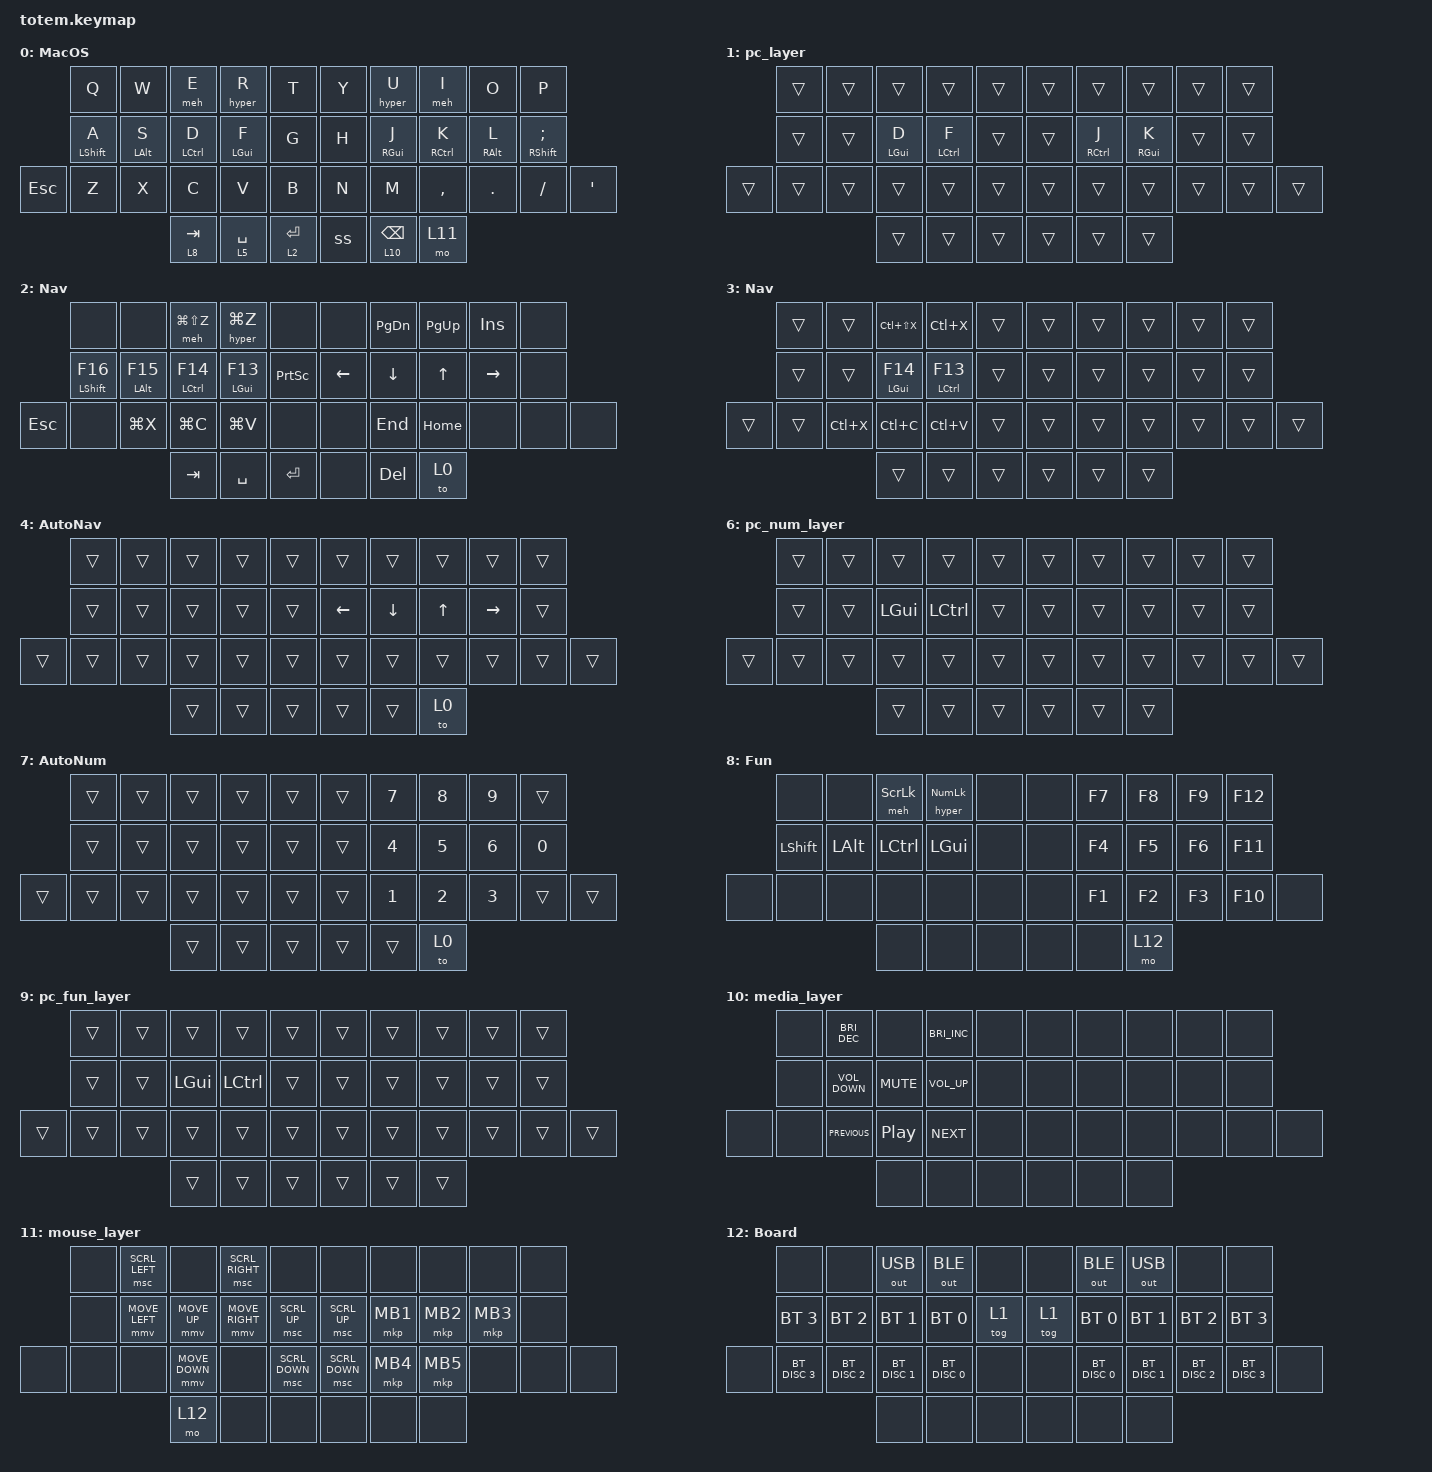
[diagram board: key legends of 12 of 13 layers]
#include <behaviors/num_word.dtsi>
#include <behaviors.dtsi>
#include <dt-bindings/zmk/bt.h>
#include <dt-bindings/zmk/keys.h>
#include <dt-bindings/zmk/outputs.h>
#include <dt-bindings/zmk/pointing.h>

#define LEFT_HAND_POS 0 1 2 3 4 10 11 12 13 14 20 21 22 23 24 25
#define RIGHT_HAND_POS 5 6 7 8 9 15 16 17 18 19 26 27 28 29 30 31
#define THUMB_POS 32 33 34 35 36 37

/ {
    macros {
        meh: meh {
            compatible = "zmk,behavior-macro";
            #binding-cells = <0>;
            wait-ms = <0>;
            tap-ms = <0>;
            bindings =
                <&macro_press>,
                <&kp LCTRL &kp LSHFT &kp LALT>,
                <&macro_pause_for_release>,
                <&macro_release>,
                <&kp LCTRL &kp LSHFT &kp LALT>;
        };

        hyper: hyper {
            compatible = "zmk,behavior-macro";
            #binding-cells = <0>;
            wait-ms = <0>;
            tap-ms = <0>;
            bindings =
                <&macro_press>,
                <&kp LCTRL &kp LSHFT &kp LALT &kp LGUI>,
                <&macro_pause_for_release>,
                <&macro_release>,
                <&kp LCTRL &kp LSHFT &kp LALT &kp LGUI>;
        };
    };

    behaviors {
        hml: home_row_mod_left {
            compatible = "zmk,behavior-hold-tap";
            #binding-cells = <2>;
            flavor = "balanced";
            tapping-term-ms = <280>;
            quick-tap-ms = <300>;
            require-prior-idle-ms = <150>;
            retro-tap;
            bindings = <&kp>, <&kp>;

            hold-trigger-key-positions = <RIGHT_HAND_POS THUMB_POS>;
            hold-trigger-on-release;
        };

        hmr: home_row_mod_right {
            compatible = "zmk,behavior-hold-tap";
            #binding-cells = <2>;
            flavor = "balanced";
            tapping-term-ms = <280>;
            quick-tap-ms = <300>;
            require-prior-idle-ms = <150>;
            retro-tap;
            bindings = <&kp>, <&kp>;

            hold-trigger-key-positions = <LEFT_HAND_POS THUMB_POS>;
            hold-trigger-on-release;
        };

        lmeh: left_meh_mod {
            compatible = "zmk,behavior-hold-tap";
            #binding-cells = <2>;
            flavor = "balanced";
            tapping-term-ms = <280>;
            quick-tap-ms = <300>;
            require-prior-idle-ms = <150>;
            retro-tap;
            bindings = <&meh>, <&kp>;

            hold-trigger-key-positions = <RIGHT_HAND_POS THUMB_POS>;
            hold-trigger-on-release;
        };

        lhyp: left_hyper_mod {
            compatible = "zmk,behavior-hold-tap";
            #binding-cells = <2>;
            flavor = "balanced";
            tapping-term-ms = <280>;
            quick-tap-ms = <300>;
            require-prior-idle-ms = <150>;
            retro-tap;
            bindings = <&hyper>, <&kp>;

            hold-trigger-key-positions = <RIGHT_HAND_POS THUMB_POS>;
            hold-trigger-on-release;
        };

        rhyp: right_hyper_mod {
            compatible = "zmk,behavior-hold-tap";
            #binding-cells = <2>;
            flavor = "balanced";
            tapping-term-ms = <280>;
            quick-tap-ms = <300>;
            require-prior-idle-ms = <150>;
            retro-tap;
            bindings = <&hyper>, <&kp>;

            hold-trigger-key-positions = <LEFT_HAND_POS THUMB_POS>;
            hold-trigger-on-release;
        };

        rmeh: right_meh_mod {
            compatible = "zmk,behavior-hold-tap";
            #binding-cells = <2>;
            flavor = "balanced";
            tapping-term-ms = <280>;
            quick-tap-ms = <300>;
            require-prior-idle-ms = <150>;
            retro-tap;
            bindings = <&meh>, <&kp>;

            hold-trigger-key-positions = <LEFT_HAND_POS THUMB_POS>;
            hold-trigger-on-release;
        };

        lts: layer_tap_sticky {
            compatible = "zmk,behavior-hold-tap";
            bindings = <&mo>, <&sk>;

            #binding-cells = <2>;
            tapping-term-ms = <200>;
        };

        ss: super_shift {
            compatible = "zmk,behavior-tap-dance";
            #binding-cells = <0>;
            bindings = <&lts 2 LEFT_SHIFT>, <&caps_word>;
        };

        htc: hold_tap_combo {
            compatible = "zmk,behavior-hold-tap";
            bindings = <&kp>, <&kp>;

            #binding-cells = <2>;
            tapping-term-ms = <185>;
            require-prior-idle-ms = <20>;
            flavor = "tap-preferred";
        };

        nav_word: nav_word {
            compatible = "zmk,behavior-auto-layer";
            #binding-cells = <1>;
            continue-list = <LEFT DOWN UP RIGHT PG_DN PG_UP INSERT END HOME TAB BACKSPACE DELETE K_UNDO K_REDO>;
            ignore-modifiers;
        };

        mht: mod_hold_transparent {
            compatible = "zmk,behavior-hold-tap";
            bindings = <&kp>, <&trans>;

            #binding-cells = <2>;
            tapping-term-ms = <200>;
            require-prior-idle-ms = <200>;
            flavor = "tap-unless-interrupted";
        };

        hypht: hyper_hold_transparent {
            compatible = "zmk,behavior-hold-tap";
            bindings = <&lhyp>, <&trans>;

            #binding-cells = <2>;
            tapping-term-ms = <200>;
            require-prior-idle-ms = <200>;
            flavor = "tap-unless-interrupted";
        };

        mehht: meh_hold_transparent {
            compatible = "zmk,behavior-hold-tap";
            bindings = <&lmeh>, <&trans>;

            #binding-cells = <2>;
            tapping-term-ms = <200>;
            require-prior-idle-ms = <200>;
            flavor = "tap-unless-interrupted";
        };
    };

    /* Ported from fleetsing/zmk-config-old; old 3x5+3 bottom-row positions are shifted for Totem. */

    combos {
        compatible = "zmk,combos";

        /* Symbol combos: slightly more time to chord intentionally, modest idle gate. */

        combo_euro_dollar {
            bindings = <&htc LA(NUMBER_4) RS(NUMBER_4)>;
            key-positions = <4 14>;
            timeout-ms = <32>;
            require-prior-idle-ms = <60>;
            layers = <0 5>;
        };

        combo_pc_euro_dollar {
            bindings = <&htc RA(NUMBER_4) RA(E)>;
            key-positions = <4 14>;
            timeout-ms = <32>;
            require-prior-idle-ms = <60>;
            layers = <1 6>;
        };

        combo_at_caret {
            bindings = <&htc RS(RIGHT_BRACKET) LA(NUMBER_2)>;
            key-positions = <14 25>;
            timeout-ms = <32>;
            require-prior-idle-ms = <60>;
            layers = <0 5 1 6>;
        };

        combo_colon_semicolon {
            bindings = <&htc RS(COMMA) RS(PERIOD)>;
            key-positions = <3 13>;
            timeout-ms = <32>;
            require-prior-idle-ms = <60>;
            layers = <0 5 1 6>;
        };

        combo_apostrophe_quote {
            bindings = <&htc RS(NUMBER_2) BACKSLASH>;
            key-positions = <13 24>;
            timeout-ms = <32>;
            require-prior-idle-ms = <60>;
            layers = <0 5 1 6>;
        };

        combo_plus_equals {
            bindings = <&htc RS(NUMBER_0) MINUS>;
            key-positions = <12 2>;
            timeout-ms = <32>;
            require-prior-idle-ms = <60>;
            layers = <0 5 1 6>;
        };

        combo_minus_underscore {
            bindings = <&htc RS(SLASH) SLASH>;
            key-positions = <12 23>;
            timeout-ms = <32>;
            require-prior-idle-ms = <60>;
            layers = <0 5 1 6>;
        };

        combo_asterisk_percentage {
            bindings = <&htc RS(NUMBER_5) RS(BACKSLASH)>;
            key-positions = <1 11>;
            timeout-ms = <32>;
            require-prior-idle-ms = <60>;
            layers = <0 5 1 6>;
        };

        combo_slash_backslash {
            bindings = <&htc RS(LA(NUMBER_7)) RS(NUMBER_7)>;
            key-positions = <11 22>;
            timeout-ms = <32>;
            require-prior-idle-ms = <60>;
            layers = <0 5>;
        };

        combo_pc_slash_backslash {
            bindings = <&htc RA(EQUAL) RS(NUMBER_7)>;
            key-positions = <11 22>;
            timeout-ms = <32>;
            require-prior-idle-ms = <60>;
            layers = <1 6>;
        };

        combo_ampersand_hash {
            bindings = <&htc RS(NUMBER_3) RS(NUMBER_6)>;
            key-positions = <5 15>;
            timeout-ms = <32>;
            require-prior-idle-ms = <60>;
            layers = <0 5 1 6>;
        };

        combo_tilde_pipe {
            bindings = <&htc LA(NUMBER_7) LA(RIGHT_BRACKET)>;
            key-positions = <15 26>;
            timeout-ms = <32>;
            require-prior-idle-ms = <60>;
            layers = <0 5>;
        };

        combo_pc_tilde_pipe {
            bindings = <&htc RA(BACKSLASH) RA(RIGHT_BRACKET)>;
            key-positions = <15 26>;
            timeout-ms = <32>;
            require-prior-idle-ms = <60>;
            layers = <1 6>;
        };

        combo_left_parenth_brace {
            bindings = <&htc RS(LA(NUMBER_8)) RS(NUMBER_8)>;
            key-positions = <6 16>;
            timeout-ms = <32>;
            require-prior-idle-ms = <60>;
            layers = <0 5>;
        };

        combo_pc_left_parenth_brace {
            bindings = <&htc RA(NUMBER_7) RS(NUMBER_8)>;
            key-positions = <16 6>;
            timeout-ms = <32>;
            require-prior-idle-ms = <60>;
            layers = <1 6>;
        };

        combo_left_bracket_lesser {
            bindings = <&htc GRAVE LA(NUMBER_8)>;
            key-positions = <16 27>;
            timeout-ms = <32>;
            require-prior-idle-ms = <60>;
            layers = <0 5 1 6>;
        };

        combo_right_parenth_brace {
            bindings = <&htc LA(RS(NUMBER_9)) RS(NUMBER_9)>;
            key-positions = <7 17>;
            timeout-ms = <32>;
            require-prior-idle-ms = <60>;
            layers = <0 5>;
        };

        combo_pc_right_parenth_brace {
            bindings = <&htc RA(NUMBER_0) RS(NUMBER_9)>;
            key-positions = <7 17>;
            timeout-ms = <32>;
            require-prior-idle-ms = <60>;
            layers = <1 6>;
        };

        combo_right_bracket_greater {
            bindings = <&htc RS(GRAVE) LA(NUMBER_9)>;
            key-positions = <17 28>;
            timeout-ms = <32>;
            require-prior-idle-ms = <60>;
            layers = <0 5 1 6>;
        };

        combo_grave_infinity {
            bindings = <&htc LA(NUMBER_5) EQUAL>;
            key-positions = <8 18>;
            timeout-ms = <32>;
            require-prior-idle-ms = <60>;
            layers = <0 5 1 6>;
        };

        /* Utility combos: tighter timing, stronger idle gate. */

        combo_tab {
            bindings = <&kp TAB>;
            key-positions = <13 12>;
            timeout-ms = <22>;
            require-prior-idle-ms = <110>;
            layers = <0 1 2 3 5 6>;
        };

        combo_tab_back {
            bindings = <&kp RS(TAB)>;
            key-positions = <12 11>;
            timeout-ms = <22>;
            require-prior-idle-ms = <110>;
            layers = <0 1 2 3 5 6>;
        };

        combo_backspace {
            bindings = <&kp BACKSPACE>;
            key-positions = <16 17>;
            timeout-ms = <22>;
            require-prior-idle-ms = <110>;
            layers = <0 1 2 3 5 6>;
        };

        combo_delete {
            bindings = <&kp DELETE>;
            key-positions = <17 18>;
            timeout-ms = <22>;
            require-prior-idle-ms = <110>;
            layers = <0 1 2 3 5 6>;
        };

        combo_lesseror_trademark {
            bindings = <&mt LA(BACKSLASH) LA(GRAVE)>;
            key-positions = <18 29>;
            timeout-ms = <32>;
            require-prior-idle-ms = <60>;
            layers = <0 5>;
        };

        combo_greateror_copyright {
            bindings = <&mt LA(NUMBER_1) LA(RS(GRAVE))>;
            key-positions = <19 30>;
            timeout-ms = <32>;
            require-prior-idle-ms = <60>;
            layers = <0 5>;
        };

        /* Layer combos: make accidental toggles harder than symbol entry. */

        combo_nav_layer {
            bindings = <&nav_word 4>;
            key-positions = <16 18>;
            timeout-ms = <28>;
            require-prior-idle-ms = <140>;
            layers = <0 1>;
        };

        combo_num_layer {
            bindings = <&num_word 7>;
            key-positions = <27 29>;
            timeout-ms = <28>;
            require-prior-idle-ms = <140>;
            layers = <0 1 2 3>;
        };
    };

    keymap {
        compatible = "zmk,keymap";

        macos_layer {
            bindings = <
            &kp Q              &kp W        &lmeh 0 E     &lhyp 0 R    &kp T          &kp Y  &rhyp 0 U         &rmeh 0 I     &kp O        &kp P
            &hml LEFT_SHIFT A  &hml LALT S  &hml LCTRL D  &hml LGUI F  &kp G          &kp H  &hmr RGUI J       &hmr RCTRL K  &hmr RALT L  &hmr RIGHT_SHIFT SEMI
&kp ESCAPE  &kp Z              &kp X        &kp C         &kp V        &kp B          &kp N  &kp M             &kp COMMA     &kp DOT      &kp SLASH              &kp APOS
                                            &lt 8 TAB     &lt 5 SPACE  &lt 2 ENTER    &ss    &lt 10 BACKSPACE  &mo 11
            >;

            label = "MacOS";
        };

        pc_layer {
            bindings = <
        &trans  &trans  &trans           &trans               &trans    &trans  &trans                &trans            &trans  &trans
        &trans  &trans  &hml LEFT_GUI D  &hml LEFT_CONTROL F  &trans    &trans  &hmr RIGHT_CONTROL J  &hmr RIGHT_GUI K  &trans  &trans
&trans  &trans  &trans  &trans           &trans               &trans    &trans  &trans                &trans            &trans  &trans  &trans
                        &trans           &trans               &trans    &trans  &trans                &trans
            >;
        };

        nav_layer {
            bindings = <
            &none                &none              &lmeh 0 LG(LS(Z))      &lhyp 0 LG(Z)      &none              &none     &kp PG_DN   &kp PG_UP  &kp INSERT  &none
            &hml LEFT_SHIFT F16  &hml LEFT_ALT F15  &hml LEFT_CONTROL F14  &hml LEFT_GUI F13  &kp PRINTSCREEN    &kp LEFT  &kp DOWN    &kp UP     &kp RIGHT   &none
&kp ESCAPE  &none                &kp LG(X)          &kp LG(C)              &kp LG(V)          &none              &none     &kp END     &kp HOME   &none       &none  &none
                                                    &kp TAB                &kp SPACE          &kp ENTER          &none     &kp DELETE  &to 0
            >;

            label = "Nav";
        };

        pc_nav_layer {
            bindings = <
        &trans  &trans     &kp LC(LS(X))      &kp LC(X)              &trans    &trans  &trans  &trans  &trans  &trans
        &trans  &trans     &hml LEFT_GUI F14  &hml LEFT_CONTROL F13  &trans    &trans  &trans  &trans  &trans  &trans
&trans  &trans  &kp LC(X)  &kp LC(C)          &kp LC(V)              &trans    &trans  &trans  &trans  &trans  &trans  &trans
                           &trans             &trans                 &trans    &trans  &trans  &trans
            >;

            label = "Nav ";
        };

        autonav_layer {
            bindings = <
        &trans  &trans  &trans  &trans  &trans    &trans          &trans          &trans        &trans           &trans
        &trans  &trans  &trans  &trans  &trans    &kp LEFT_ARROW  &kp DOWN_ARROW  &kp UP_ARROW  &kp RIGHT_ARROW  &trans
&trans  &trans  &trans  &trans  &trans  &trans    &trans          &trans          &trans        &trans           &trans  &trans
                        &trans  &trans  &trans    &trans          &trans          &to 0
            >;

            label = "AutoNav";
        };

        num_layer {
            bindings = <
       &none           &none         &kp LA(LC(LEFT_SHIFT))  &kp LA(LC(LG(LEFT_SHIFT)))  &none    &none   &kp N7         &kp N8  &kp N9  &none
       &kp LEFT_SHIFT  &kp LEFT_ALT  &kp LEFT_CONTROL        &kp LEFT_GUI                &none    &none   &kp N4         &kp N5  &kp N6  &kp N0
&none  &none           &none         &none                   &none                       &none    &none   &kp N1         &kp N2  &kp N3  &none   &none
                                     &none                   &none                       &none    &kp N0  &kp BACKSPACE  &to 0
            >;

            label = "Num";
        };

        pc_num_layer {
            bindings = <
        &trans  &trans  &trans        &trans            &trans    &trans  &trans  &trans  &trans  &trans
        &trans  &trans  &kp LEFT_GUI  &kp LEFT_CONTROL  &trans    &trans  &trans  &trans  &trans  &trans
&trans  &trans  &trans  &trans        &trans            &trans    &trans  &trans  &trans  &trans  &trans  &trans
                        &trans        &trans            &trans    &trans  &trans  &trans
            >;
        };

        autonum_layer {
            bindings = <
        &trans  &trans  &trans  &trans  &trans    &trans  &kp N7  &kp N8  &kp N9  &trans
        &trans  &trans  &trans  &trans  &trans    &trans  &kp N4  &kp N5  &kp N6  &kp N0
&trans  &trans  &trans  &trans  &trans  &trans    &trans  &kp N1  &kp N2  &kp N3  &trans  &trans
                        &trans  &trans  &trans    &trans  &trans  &to 0
            >;

            label = "AutoNum";
        };

        fun_layer {
            bindings = <
       &none           &none         &lmeh 0 SCROLLLOCK  &lhyp 0 KP_NUMLOCK  &none    &none  &kp F7  &kp F8  &kp F9  &kp F12
       &kp LEFT_SHIFT  &kp LEFT_ALT  &kp LEFT_CONTROL    &kp LEFT_GUI        &none    &none  &kp F4  &kp F5  &kp F6  &kp F11
&none  &none           &none         &none               &none               &none    &none  &kp F1  &kp F2  &kp F3  &kp F10  &none
                                     &none               &none               &none    &none  &none   &mo 12
            >;

            label = "Fun";
        };

        pc_fun_layer {
            bindings = <
        &trans  &trans  &trans        &trans            &trans    &trans  &trans  &trans  &trans  &trans
        &trans  &trans  &kp LEFT_GUI  &kp LEFT_CONTROL  &trans    &trans  &trans  &trans  &trans  &trans
&trans  &trans  &trans  &trans        &trans            &trans    &trans  &trans  &trans  &trans  &trans  &trans
                        &trans        &trans            &trans    &trans  &trans  &trans
            >;
        };

        media_layer {
            bindings = <
       &none  &kp C_BRIGHTNESS_DEC  &none             &kp C_BRIGHTNESS_INC  &none    &none  &none  &none  &none  &none
       &none  &kp C_VOLUME_DOWN     &kp C_MUTE        &kp C_VOLUME_UP       &none    &none  &none  &none  &none  &none
&none  &none  &kp C_PREVIOUS        &kp C_PLAY_PAUSE  &kp C_NEXT            &none    &none  &none  &none  &none  &none  &none
                                    &none             &none                 &none    &none  &none  &none
            >;
        };

        mouse_layer {
            bindings = <
       &none  &msc SCRL_LEFT  &none           &msc SCRL_RIGHT  &none             &none           &none     &none     &none     &none
       &none  &mmv MOVE_LEFT  &mmv MOVE_UP    &mmv MOVE_RIGHT  &msc SCRL_UP      &msc SCRL_UP    &mkp MB1  &mkp MB2  &mkp MB3  &none
&none  &none  &none           &mmv MOVE_DOWN  &none            &msc SCRL_DOWN    &msc SCRL_DOWN  &mkp MB4  &mkp MB5  &none     &none  &none
                              &mo 12          &none            &none             &none           &none     &none
            >;
        };

        board_layer {
            bindings = <
       &none          &none          &out OUT_USB   &out OUT_BLE   &none     &none   &out OUT_BLE   &out OUT_USB   &none          &none
       &bt BT_SEL 3   &bt BT_SEL 2   &bt BT_SEL 1   &bt BT_SEL 0   &tog 1    &tog 1  &bt BT_SEL 0   &bt BT_SEL 1   &bt BT_SEL 2   &bt BT_SEL 3
&none  &bt BT_DISC 3  &bt BT_DISC 2  &bt BT_DISC 1  &bt BT_DISC 0  &none     &none   &bt BT_DISC 0  &bt BT_DISC 1  &bt BT_DISC 2  &bt BT_DISC 3  &none
                                     &none          &none          &none     &none   &none          &none
            >;

            label = "Board";
        };
    };

    conditional_layers {
        compatible = "zmk,conditional-layers";

        pc_nav_condition {
            if-layers = <1 2>;
            then-layer = <3>;
        };

        pc_num_condition {
            if-layers = <1 5>;
            then-layer = <6>;
        };

        pc_fun_layer {
            if-layers = <1 8>;
            then-layer = <9>;
        };
    };
};

/* Double-tap and hold a thumb layer-tap repeats its tap key (space/backspace/enter)
 * instead of activating the layer, mirroring the home-row quick-tap window. */

&lt {
    quick-tap-ms = <300>;
};

&num_word {
    continue-list = <
        BACKSPACE DELETE DOT COMMA
        PLUS MINUS STAR FSLH EQUAL
        LEFT_PARENTHESIS RIGHT_PARENTHESIS
        LEFT_BRACKET RIGHT_BRACKET
        LEFT_BRACE RIGHT_BRACE
        CARET PERCENT EXCLAMATION
        LESS_THAN GREATER_THAN
    >;

    ignore-modifiers;
};
